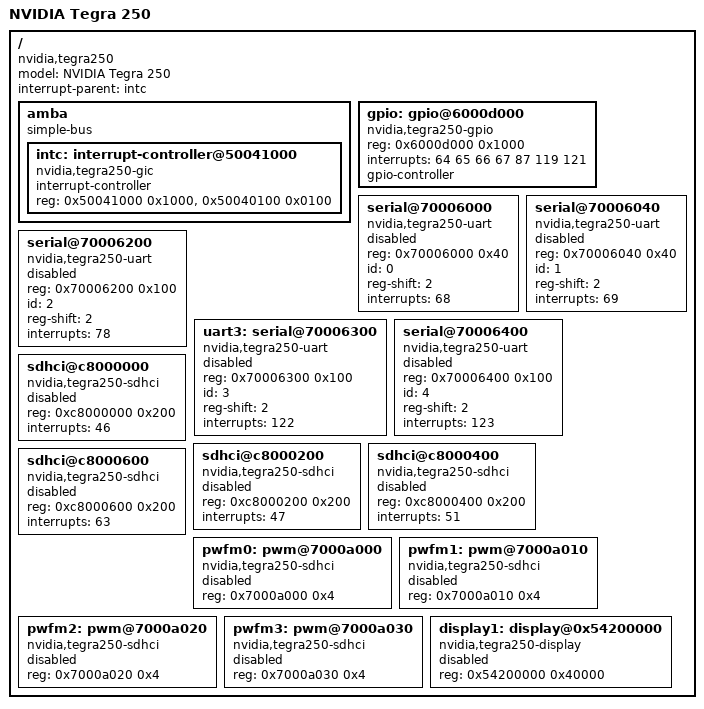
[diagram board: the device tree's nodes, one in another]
/include/ "../../../../../dts/skeleton.dtsi"

/ {
	model = "NVIDIA Tegra 250";
	compatible = "nvidia,tegra250";
	interrupt-parent = <&intc>;

	amba {
		compatible = "simple-bus";
		#address-cells = <1>;
		#size-cells = <1>;
		ranges;

		intc: interrupt-controller@50041000 {
			compatible = "nvidia,tegra250-gic", "arm,gic";
			interrupt-controller;
			#interrupt-cells = <1>;
			reg = < 0x50041000 0x1000 >,
			      < 0x50040100 0x0100 >;
		};
	};

	gpio: gpio@6000d000 {
		compatible = "nvidia,tegra250-gpio", "ns16550";
		reg = < 0x6000d000 0x1000 >;
		interrupts = < 64 65 66 67 87 119 121 >;
		#gpio-cells = <2>;
		gpio-controller;
	};

	serial@70006000 {
		compatible = "nvidia,tegra250-uart", "ns16550";
		reg = <0x70006000 0x40>;
		id = <0>;
		reg-shift = <2>;
		interrupts = < 68 >;
		status = "disabled";
	};

	serial@70006040 {
		compatible = "nvidia,tegra250-uart", "ns16550";
		reg = <0x70006040 0x40>;
		id = <1>;
		reg-shift = <2>;
		interrupts = < 69 >;
		status = "disabled";
	};

	serial@70006200 {
		compatible = "nvidia,tegra250-uart", "ns16550";
		reg = <0x70006200 0x100>;
		id = <2>;
		reg-shift = <2>;
		interrupts = < 78 >;
		status = "disabled";
	};

	uart3: serial@70006300 {
		compatible = "nvidia,tegra250-uart", "ns16550";
		reg = <0x70006300 0x100>;
		id = <3>;
		reg-shift = <2>;
		interrupts = < 122 >;
		status = "disabled";
	};

	serial@70006400 {
		compatible = "nvidia,tegra250-uart", "ns16550";
		reg = <0x70006400 0x100>;
		id = <4>;
		reg-shift = <2>;
		interrupts = < 123 >;
		status = "disabled";
	};

	sdhci@c8000000 {
		compatible = "nvidia,tegra250-sdhci";
		reg = <0xc8000000 0x200>;
		interrupts = < 46 >;
		status = "disabled";
	};

	sdhci@c8000200 {
		compatible = "nvidia,tegra250-sdhci";
		reg = <0xc8000200 0x200>;
		interrupts = < 47 >;
		status = "disabled";
	};

	sdhci@c8000400 {
		compatible = "nvidia,tegra250-sdhci";
		reg = <0xc8000400 0x200>;
		interrupts = < 51 >;
		status = "disabled";
	};

	sdhci@c8000600 {
		compatible = "nvidia,tegra250-sdhci";
		reg = <0xc8000600 0x200>;
		interrupts = < 63 >;
		status = "disabled";
	};

	pwfm0: pwm@7000a000 {
		compatible = "nvidia,tegra250-sdhci";
		reg = <0x7000a000 0x4>;
		status = "disabled";
	};

	pwfm1: pwm@7000a010 {
		compatible = "nvidia,tegra250-sdhci";
		reg = <0x7000a010 0x4>;
		status = "disabled";
	};

	pwfm2: pwm@7000a020 {
		compatible = "nvidia,tegra250-sdhci";
		reg = <0x7000a020 0x4>;
		status = "disabled";
	};

	pwfm3: pwm@7000a030 {
		compatible = "nvidia,tegra250-sdhci";
		reg = <0x7000a030 0x4>;
		status = "disabled";
	};

	display1: display@0x54200000 {
		compatible = "nvidia,tegra250-display";
		reg = <0x54200000 0x40000>;
		status = "disabled";
	};
};

